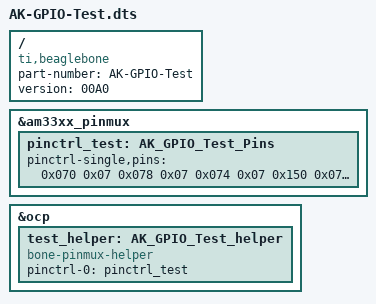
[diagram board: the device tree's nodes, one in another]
/*  
* Copyright (C) 2012 Texas Instruments Incorporated - http://www.ti.com/
*
* This program is free software; you can redistribute it and/or modify
* it under the terms of the GNU General Purpose License Version 2 as
* published by the Free Software Foundation
*
* Original from: github.com/jadonk/validation-scripts/blob/master/test-capemgr/ 
*
* Modified by Alexander Kulpanov for safex project
*/

/dts-v1/;
/plugin/;

/{
       compatible = "ti,beaglebone", "ti,beaglebone-black";
       part-number = "AK-GPIO-Test";
       version = "00A0";

       fragment@0 {
             target = <&am33xx_pinmux>;
            
             __overlay__ {
                  pinctrl_test: AK_GPIO_Test_Pins {
			pinctrl-single,pins = <

				0x070 0x07  /* P9_11 60 OUTPUT MODE7 - valve_H */
				0x078 0x07  /* P9_12 61 OUTPUT MODE7 - valve_N */
				0x074 0x07  /* P9_13 61 OUTPUT MODE7 - alive */	
				0x150 0x07  /* P9_22 61 OUTPUT MODE7 - beep-alert */
				0x184 0x07  /* P9_24 61 OUTPUT MODE7 - GC shutdown */						
				0x07c 0x27  /* P8_26    INPUT  MODE7 pulldown - Input remote stop/emergency stop */
				
/*				0x184 0x2f  /* P9_24 15 INPUT  MODE7 none     - Input */
/*				0x034 0x37  /* P8_11 45 INPUT  MODE7 pullup   - Input */
/*				0x030 0x27  /* P8_12 44 INPUT  MODE7 pulldown - Input */
/*				0x024 0x2f  /* P8_13 23 INPUT  MODE7 none     - Input */
                       
                   /* OUTPUT  GPIO(mode7) 0x07 pulldown, 0x17 pullup, 0x?f no pullup/down */
			       /* INPUT   GPIO(mode7) 0x27 pulldown, 0x37 pullup, 0x?f no pullup/down */

			>;
		  };
             };
       };

       fragment@1 {
		target = <&ocp>;
		__overlay__ {
			test_helper: AK_GPIO_Test_helper {
				compatible = "bone-pinmux-helper";
				pinctrl-names = "default";
				pinctrl-0 = <&pinctrl_test>;
				status = "okay";
			};
		};
	};
};
